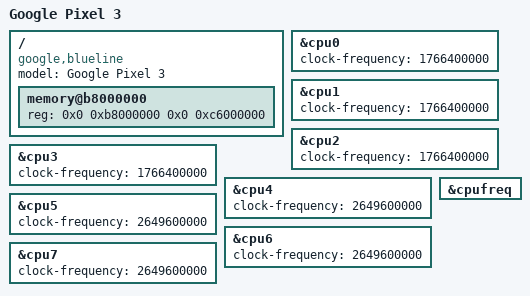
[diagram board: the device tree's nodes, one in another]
/dts-v1/;
// SPDX-License-Identifier: BSD-2-Clause-Patent
/*
 * Google Pixel 3 (blueline), Qualcomm SDM845 - board hardware description.
 *
 * UniXNU compiles this tree and derives the Apple device tree (kernel.macho.adt) from it:
 *   - the memory node becomes /chosen/dram-base and /chosen/dram-size, and must match
 *     [payload] dram_size of board.toml
 *   - the enabled /cpus children become the ADT /cpus (boot CPU first)
 *   - each node carrying "unixnu,adt-name" is exported under the ADT /arm-io window
 * The CPUs, PSCI and the GIC come from sdm845.dtsi (UniXNU-sdm845-common).
 */

/include/ "sdm845.dtsi"

/ {
	model = "Google Pixel 3";
	compatible = "google,blueline", "qcom,sdm845";

	/*
	 * The DRAM XNU may own: the firmware's one RAM region from 0xB8000000 to the end of the RAM ABL gives the OS
	 * (0x80000000 + 0xFE0A0000 = 0x17E0A0000, 4064 MiB, read by erikkunz/pixel3-ios's probe), rounded down to 2 MiB.
	 * DarwinBoot's window ([payload.adt] owned_memory_size) is allocated from it. iOS 18 takes /chosen dram-base as the first valid page
	 * (pmap_first_pnum), so it describes that region rather than all of DRAM from 0x80000000 (run 15). Must match
	 * [payload] dram_size of board.toml.
	 */
	memory@b8000000 {
		device_type = "memory";
		reg = <0x0 0xb8000000 0x0 0xc6000000>;
	};
};

/* All eight cores, as pixel3-ios 0101. BCM2837's native 4 KiB personality supports one SMP cluster;
 * omit E/P scheduling tags here. OSM still distinguishes Silver and Gold for clock requests.
 * Nominal regular frequencies were measured by pixel3-ios; the firmware LUT determines actual requests.
 */
&cpu0 { /delete-property/ unixnu,cluster-type; clock-frequency = <1766400000>; };
&cpu1 { /delete-property/ unixnu,cluster-type; clock-frequency = <1766400000>; };
&cpu2 { /delete-property/ unixnu,cluster-type; clock-frequency = <1766400000>; };
&cpu3 { /delete-property/ unixnu,cluster-type; clock-frequency = <1766400000>; };
&cpu4 { /delete-property/ unixnu,cluster-type; clock-frequency = <2649600000>; };
&cpu5 { /delete-property/ unixnu,cluster-type; clock-frequency = <2649600000>; };
&cpu6 { /delete-property/ unixnu,cluster-type; clock-frequency = <2649600000>; };
&cpu7 { /delete-property/ unixnu,cluster-type; clock-frequency = <2649600000>; };
&cpufreq { status = "okay"; };
